AUTOSAR XML (schema 00052)
package /Components
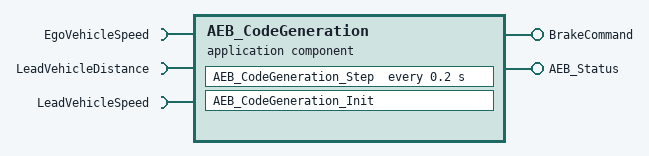
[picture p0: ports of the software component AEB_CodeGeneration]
  application sw component type AEB_CodeGeneration
    require port EgoVehicleSpeed: nonqueued-receiver-com-spec{data-element=EgoVehicleSpeed, init-value=0}, required-interface=EgoVehicleSpeed
    require port LeadVehicleDistance: nonqueued-receiver-com-spec{data-element=LeadVehicleDistance, init-value=0}, required-interface=LeadVehicleDistance
    require port LeadVehicleSpeed: nonqueued-receiver-com-spec{data-element=LeadVehicleSpeed, init-value=0}, required-interface=LeadVehicleSpeed
    provide port BrakeCommand: nonqueued-sender-com-spec{data-element=BrakeCommand, init-value=0}, provided-interface=BrakeCommand
    provide port AEB_Status: nonqueued-sender-com-spec{data-element=AEB_Status, init-value=0}, provided-interface=AEB_Status
    behavior AEB_CodeGeneration_IB: handle-termination-and-restart=NO-SUPPORT
      timing event Event_AEB_CodeGeneration_Step: start-on-event=AEB_CodeGeneration_Step, period=0.2
      runnable AEB_CodeGeneration_Init
      runnable AEB_CodeGeneration_Step
        data-read-access:
          access IN_EgoVehicleSpeed_EgoVehicleSpeed: accessed-variable=EgoVehicleSpeed.EgoVehicleSpeed
          access IN_LeadVehicleDistance_LeadVehicleDistance: accessed-variable=LeadVehicleDistance.LeadVehicleDistance
          access IN_LeadVehicleSpeed_LeadVehicleSpeed: accessed-variable=LeadVehicleSpeed.LeadVehicleSpeed
        data-write-access:
          access OUT_BrakeCommand_BrakeCommand: accessed-variable=BrakeCommand.BrakeCommand
          access OUT_AEB_Status_AEB_Status: accessed-variable=AEB_Status.AEB_Status
